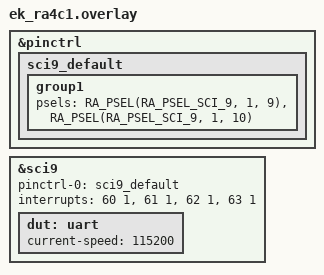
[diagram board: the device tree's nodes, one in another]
/*
 * Copyright (c) 2025 Renesas Electronics Corporation
 * SPDX-License-Identifier: Apache-2.0
 */

&pinctrl {
	sci9_default: sci9_default {
		group1 {
			/* tx rx */
			psels = <RA_PSEL(RA_PSEL_SCI_9, 1, 9)>,
				<RA_PSEL(RA_PSEL_SCI_9, 1, 10)>;
		};
	};
};

&sci9 {
	pinctrl-0 = <&sci9_default>;
	pinctrl-names = "default";
	interrupts = <60 1>, <61 1>, <62 1>, <63 1>;
	interrupt-names = "rxi", "txi", "tei", "eri";
	status = "okay";

	dut: uart {
		current-speed = <115200>;
		status = "okay";
	};
};
